VERSION ""

NS_ :

BS_: 500

BU_: Vector__XXX

BO_ 2 MSG_002: 8 Vector__XXX
 SG_ Steering_Angle : 0|16@1- (0.1,0) [-3276.8|3276.7] "��" Vector__XXX
 SG_ Steering_Rate : 40|8@0+ (4,0) [0|1020] "��/s" Vector__XXX

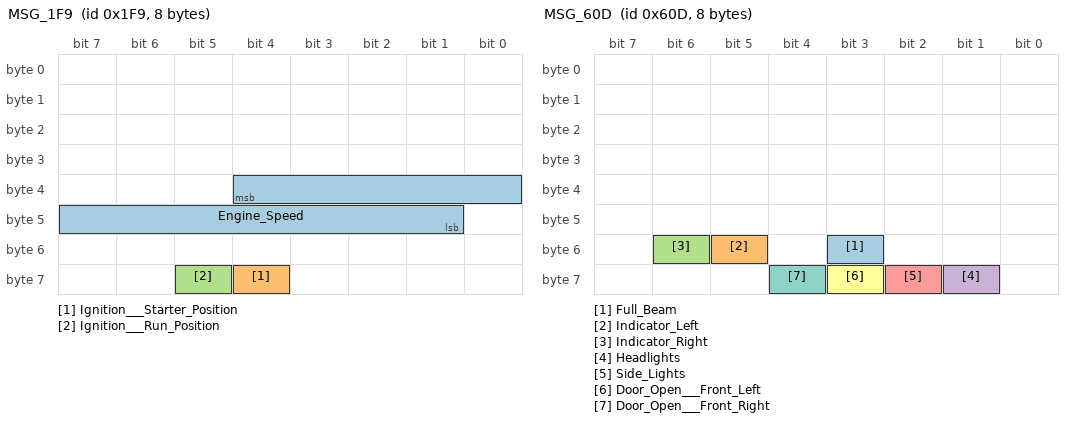
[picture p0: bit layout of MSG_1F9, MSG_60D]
BO_ 505 MSG_1F9: 8 Vector__XXX
 SG_ Engine_Speed : 36|12@0+ (2,0) [0|8190] "rpm" Vector__XXX
 SG_ Ignition___Starter_Position : 60|1@0+ (1,0) [0|0] "" Vector__XXX
 SG_ Ignition___Run_Position : 61|1@0+ (1,0) [0|0] "" Vector__XXX

BO_ 644 MSG_284: 8 Vector__XXX
 SG_ Indicated_Vehicle_Speed_kph : 16|16@0+ (0.00661,0) [0|320] "km/h" Vector__XXX
 SG_ Indicated_Vehicle_Speed_mph : 16|16@0+ (0.00410481,0) [0|198.72] "mph" Vector__XXX
 SG_ Wheel_Speed_FL_kph : 32|16@0+ (0.00541,0) [0|354] "km/h" Vector__XXX
 SG_ Wheel_Speed_FL_mph : 32|16@0+ (0.00335961,0) [0|219.834] "mph" Vector__XXX
 SG_ Wheel_Speed_FR_kph : 48|16@0+ (0.00541,0) [0|354] "km/h" Vector__XXX
 SG_ Wheel_Speed_FR_mph : 48|16@0+ (0.00335961,0) [0|219.834] "mph" Vector__XXX

BO_ 645 MSG_285: 8 Vector__XXX
 SG_ Wheel_Speed_RL_kph : 32|16@0+ (0.00537,0) [0|351] "km/h" Vector__XXX
 SG_ Wheel_Speed_RL_mph : 32|16@0+ (0.00333477,0) [0|217.971] "mph" Vector__XXX
 SG_ Wheel_Speed_RR_kph : 48|16@0+ (0.00537,0) [0|351] "km/h" Vector__XXX
 SG_ Wheel_Speed_RR_mph : 48|16@0+ (0.00333477,0) [0|217.971] "mph" Vector__XXX

BO_ 658 MSG_292: 8 Vector__XXX
 SG_ Brake_Position : 8|8@0+ (1.25,0) [0|100] "" Vector__XXX
 SG_ Yaw_Rate : 28|12@0+ (1,-2048) [-2048|2047] "" Vector__XXX
 SG_ Indicated_Lateral_Acceleration : 40|12@0+ (1,-2048) [-2048|2047] "" Vector__XXX
 SG_ Indicated_Longitudinal_Acceleration : 52|12@0+ (1,-2048) [-2048|2047] "" Vector__XXX

BO_ 725 MSG_2D5: 8 Vector__XXX
 SG_ Gear : 41|3@0+ (1,1) [1|8] "" Vector__XXX
 SG_ Throttle_Position : 46|10@0+ (0.125,0) [0|100] "%" Vector__XXX

BO_ 1361 MSG_551: 8 Vector__XXX
 SG_ Fuel_Consumption : 8|8@1+ (1,0) [0|255] "mm��" Vector__XXX
 SG_ Coolant_Temperature : 56|8@0+ (1,-40) [-40|200] "��C" Vector__XXX

BO_ 1376 MSG_560: 8 Vector__XXX
 SG_ Transmission_Oil_Temperature : 56|8@0+ (1,-40) [-40|215] "��C" Vector__XXX

BO_ 1436 MSG_59C: 8 Vector__XXX
 SG_ Boost_Pressure : 32|8@0+ (1,-100) [-100|155] "kPa" Vector__XXX
 SG_ Oil_Temperature : 40|8@0+ (1,-50) [-50|205] "��C" Vector__XXX

BO_ 1549 MSG_60D: 8 Vector__XXX
 SG_ Full_Beam : 51|1@0+ (1,0) [0|0] "" Vector__XXX
 SG_ Indicator_Left : 53|1@0+ (1,0) [0|0] "" Vector__XXX
 SG_ Indicator_Right : 54|1@0+ (1,0) [0|0] "" Vector__XXX
 SG_ Headlights : 57|1@0+ (1,0) [0|0] "" Vector__XXX
 SG_ Side_Lights : 58|1@0+ (1,0) [0|0] "" Vector__XXX
 SG_ Door_Open___Front_Left : 59|1@0+ (1,0) [0|0] "" Vector__XXX
 SG_ Door_Open___Front_Right : 60|1@0+ (1,0) [0|0] "" Vector__XXX
